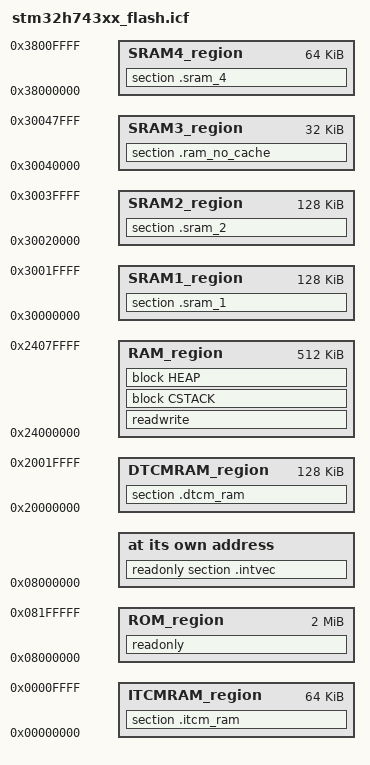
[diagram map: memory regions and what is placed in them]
/*###ICF### Section handled by ICF editor, don't touch! ****/
/*-Editor annotation file-*/
/* IcfEditorFile="$TOOLKIT_DIR$\config\ide\IcfEditor\cortex_v1_0.xml" */
/*-Specials-*/
define symbol __ICFEDIT_intvec_start__ = 0x08000000;

/*-ROM Memory Regions-*/
define symbol __ICFEDIT_region_ROM_start__ = 0x08000000;
define symbol __ICFEDIT_region_ROM_end__   = 0x081FFFFF;

/*-ITCM-RAM Memory Regions-*/
define symbol __ICFEDIT_region_ITCMRAM_start__ = 0x00000000;
define symbol __ICFEDIT_region_ITCMRAM_end__   = 0x0000FFFF;

/*-DTCM-RAM Memory Regions-*/
define symbol __ICFEDIT_region_DTCMRAM_start__ = 0x20000000;
define symbol __ICFEDIT_region_DTCMRAM_end__   = 0x2001FFFF;

/*-AXI-SRAM Memory Regions-*/
define symbol __ICFEDIT_region_RAM_start__ = 0x24000000;
define symbol __ICFEDIT_region_RAM_end__   = 0x2407FFFF;

/*-SRAM1 Memory Regions-*/
define symbol __ICFEDIT_region_SRAM1_start__ = 0x30000000;
define symbol __ICFEDIT_region_SRAM1_end__   = 0x3001FFFF;

/*-SRAM2 Memory Regions-*/
define symbol __ICFEDIT_region_SRAM2_start__ = 0x30020000;
define symbol __ICFEDIT_region_SRAM2_end__   = 0x3003FFFF;

/*-SRAM3 Memory Regions-*/
define symbol __ICFEDIT_region_SRAM3_start__ = 0x30040000;
define symbol __ICFEDIT_region_SRAM3_end__   = 0x30047FFF;

/*-SRAM4 Memory Regions-*/
define symbol __ICFEDIT_region_SRAM4_start__ = 0x38000000;
define symbol __ICFEDIT_region_SRAM4_end__   = 0x3800FFFF;

/*-Sizes-*/
define symbol __ICFEDIT_size_cstack__ = 0x800;
define symbol __ICFEDIT_size_heap__   = 0x400;
/**** End of ICF editor section. ###ICF###*/


define memory mem with size = 4G;
define region ROM_region      = mem:[from __ICFEDIT_region_ROM_start__     to __ICFEDIT_region_ROM_end__    ];
define region ITCMRAM_region  = mem:[from __ICFEDIT_region_ITCMRAM_start__ to __ICFEDIT_region_ITCMRAM_end__];
define region DTCMRAM_region  = mem:[from __ICFEDIT_region_DTCMRAM_start__ to __ICFEDIT_region_DTCMRAM_end__];
define region RAM_region      = mem:[from __ICFEDIT_region_RAM_start__     to __ICFEDIT_region_RAM_end__    ];
define region SRAM1_region    = mem:[from __ICFEDIT_region_SRAM1_start__   to __ICFEDIT_region_SRAM1_end__  ];
define region SRAM2_region    = mem:[from __ICFEDIT_region_SRAM2_start__   to __ICFEDIT_region_SRAM2_end__  ];
define region SRAM3_region    = mem:[from __ICFEDIT_region_SRAM3_start__   to __ICFEDIT_region_SRAM3_end__  ];
define region SRAM4_region    = mem:[from __ICFEDIT_region_SRAM4_start__   to __ICFEDIT_region_SRAM4_end__  ];

define block CSTACK    with alignment = 8, size = __ICFEDIT_size_cstack__   { };
define block HEAP      with alignment = 8, size = __ICFEDIT_size_heap__     { };

initialize by copy { readwrite };
do not initialize  { section .noinit };

place at address mem:__ICFEDIT_intvec_start__ { readonly section .intvec };

place in ROM_region     { readonly };
place in ITCMRAM_region { section .itcm_ram };
place in DTCMRAM_region { section .dtcm_ram };
place in RAM_region     { readwrite, block CSTACK, block HEAP };
place in SRAM1_region   { section .sram_1 };
place in SRAM2_region   { section .sram_2 };
place in SRAM3_region   { section .ram_no_cache };
place in SRAM4_region   { section .sram_4 };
